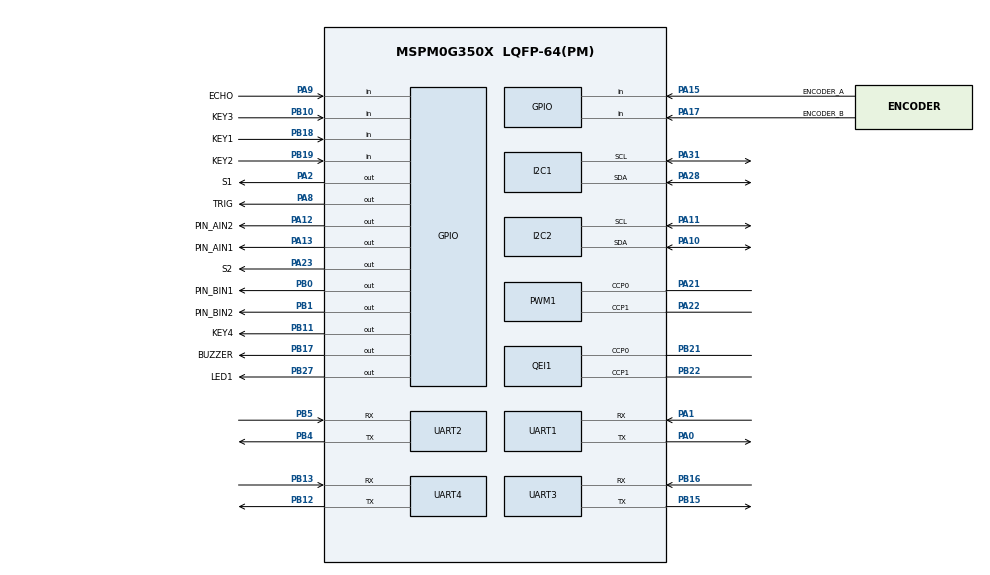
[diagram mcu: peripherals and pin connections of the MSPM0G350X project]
/**
 * @cliArgs --device "MSPM0G350X" --part "Default" --package "LQFP-64(PM)" --product "mspm0_sdk@2.10.00.04"
 * @versions {"tool":"1.26.2+4477"}
 */

/**
 * Import the modules used in this configuration.
 */
const ADC12  = scripting.addModule("/ti/driverlib/ADC12", {}, false);
const ADC121 = ADC12.addInstance();
const GPIO   = scripting.addModule("/ti/driverlib/GPIO", {}, false);
const GPIO1  = GPIO.addInstance();
const GPIO2  = GPIO.addInstance();
const GPIO3  = GPIO.addInstance();
const GPIO4  = GPIO.addInstance();
const GPIO5  = GPIO.addInstance();
const GPIO6  = GPIO.addInstance();
const GPIO7  = GPIO.addInstance();
const I2C    = scripting.addModule("/ti/driverlib/I2C", {}, false);
const I2C1   = I2C.addInstance();
const I2C2   = I2C.addInstance();
const PWM    = scripting.addModule("/ti/driverlib/PWM", {}, false);
const PWM1   = PWM.addInstance();
const QEI    = scripting.addModule("/ti/driverlib/QEI", {}, false);
const QEI1   = QEI.addInstance();
const SYSCTL = scripting.addModule("/ti/driverlib/SYSCTL");
const UART   = scripting.addModule("/ti/driverlib/UART", {}, false);
const UART1  = UART.addInstance();
const UART2  = UART.addInstance();
const UART3  = UART.addInstance();
const UART4  = UART.addInstance();

/**
 * Write custom configuration values to the imported modules.
 */
ADC121.$name                       = "TRACK";
ADC121.adcMem11chansel             = "DL_ADC12_INPUT_CHAN_12";
ADC121.adcMem0chansel              = "DL_ADC12_INPUT_CHAN_12";
ADC121.peripheral.$assign          = "ADC0";
ADC121.peripheral.adcPin12.$assign = "PA14";
ADC121.adcPin12Config.$name        = "ti_driverlib_gpio_GPIOPinGeneric16";

const Board = scripting.addModule("/ti/driverlib/Board", {}, false);

GPIO1.$name                         = "GPIO_QEI_RIGHT_MOTOR";
GPIO1.associatedPins.create(2);
GPIO1.associatedPins[0].$name       = "ENCODER_A";
GPIO1.associatedPins[0].direction   = "INPUT";
GPIO1.associatedPins[0].interruptEn = true;
GPIO1.associatedPins[0].polarity    = "RISE_FALL";
GPIO1.associatedPins[0].pin.$assign = "PA15";
GPIO1.associatedPins[1].$name       = "ENCODER_B";
GPIO1.associatedPins[1].direction   = "INPUT";
GPIO1.associatedPins[1].pin.$assign = "PA17";

GPIO2.$name                         = "GPIO_MOTOR_DIRECTION";
GPIO2.associatedPins.create(4);
GPIO2.associatedPins[0].$name       = "PIN_AIN2";
GPIO2.associatedPins[0].pin.$assign = "PA12";
GPIO2.associatedPins[1].$name       = "PIN_AIN1";
GPIO2.associatedPins[1].pin.$assign = "PA13";
GPIO2.associatedPins[2].$name       = "PIN_BIN1";
GPIO2.associatedPins[2].pin.$assign = "PB0";
GPIO2.associatedPins[3].$name       = "PIN_BIN2";
GPIO2.associatedPins[3].pin.$assign = "PB1";

GPIO3.$name                              = "GPIO_GRP_KEY";
GPIO3.port                               = "PORTB";
GPIO3.associatedPins.create(4);
GPIO3.associatedPins[0].direction        = "INPUT";
GPIO3.associatedPins[0].$name            = "KEY2";
GPIO3.associatedPins[0].assignedPin      = "19";
GPIO3.associatedPins[0].internalResistor = "PULL_UP";
GPIO3.associatedPins[0].pin.$assign      = "PB19";
GPIO3.associatedPins[1].$name            = "KEY1";
GPIO3.associatedPins[1].direction        = "INPUT";
GPIO3.associatedPins[1].pin.$assign      = "PB18";
GPIO3.associatedPins[2].$name            = "KEY3";
GPIO3.associatedPins[2].direction        = "INPUT";
GPIO3.associatedPins[2].internalResistor = "PULL_UP";
GPIO3.associatedPins[2].pin.$assign      = "PB10";
GPIO3.associatedPins[3].$name            = "KEY4";
GPIO3.associatedPins[3].pin.$assign      = "PB11";

GPIO4.$name                          = "GPIO_GRP_LED";
GPIO4.port                           = "PORTB";
GPIO4.associatedPins[0].$name        = "LED1";
GPIO4.associatedPins[0].assignedPin  = "27";
GPIO4.associatedPins[0].initialValue = "SET";
GPIO4.associatedPins[0].pin.$assign  = "PB27";

GPIO5.$name                         = "GPIO_GRP_TRACK";
GPIO5.port                          = "PORTA";
GPIO5.associatedPins.create(3);
GPIO5.associatedPins[0].$name       = "S1";
GPIO5.associatedPins[0].pin.$assign = "PA2";
GPIO5.associatedPins[1].$name       = "S2";
GPIO5.associatedPins[1].pin.$assign = "PA23";
GPIO5.associatedPins[2].$name       = "S0";

GPIO6.$name                         = "GPIO_GRP_BUZZER";
GPIO6.port                          = "PORTB";
GPIO6.associatedPins[0].$name       = "BUZZER";
GPIO6.associatedPins[0].pin.$assign = "PB17";

GPIO7.$name                         = "GPIO_GRP_HCSR04";
GPIO7.port                          = "PORTA";
GPIO7.associatedPins.create(2);
GPIO7.associatedPins[0].$name       = "TRIG";
GPIO7.associatedPins[0].pin.$assign = "PA8";
GPIO7.associatedPins[1].$name       = "ECHO";
GPIO7.associatedPins[1].direction   = "INPUT";
GPIO7.associatedPins[1].pin.$assign = "PA9";

I2C1.$name                             = "I2C_OLED";
I2C1.peripheral.$assign                = "I2C0";
I2C1.peripheral.sdaPin.$assign         = "PA28";
I2C1.peripheral.sclPin.$assign         = "PA31";
I2C1.sdaPinConfig.hideOutputInversion  = scripting.forceWrite(false);
I2C1.sdaPinConfig.onlyInternalResistor = scripting.forceWrite(false);
I2C1.sdaPinConfig.passedPeripheralType = scripting.forceWrite("Digital");
I2C1.sdaPinConfig.$name                = "ti_driverlib_gpio_GPIOPinGeneric4";
I2C1.sclPinConfig.hideOutputInversion  = scripting.forceWrite(false);
I2C1.sclPinConfig.onlyInternalResistor = scripting.forceWrite(false);
I2C1.sclPinConfig.passedPeripheralType = scripting.forceWrite("Digital");
I2C1.sclPinConfig.$name                = "ti_driverlib_gpio_GPIOPinGeneric5";

I2C2.$name                             = "I2C_MPU";
I2C2.peripheral.$assign                = "I2C1";
I2C2.peripheral.sdaPin.$assign         = "PA10";
I2C2.peripheral.sclPin.$assign         = "PA11";
I2C2.sdaPinConfig.hideOutputInversion  = scripting.forceWrite(false);
I2C2.sdaPinConfig.onlyInternalResistor = scripting.forceWrite(false);
I2C2.sdaPinConfig.passedPeripheralType = scripting.forceWrite("Digital");
I2C2.sdaPinConfig.$name                = "ti_driverlib_gpio_GPIOPinGeneric6";
I2C2.sclPinConfig.hideOutputInversion  = scripting.forceWrite(false);
I2C2.sclPinConfig.onlyInternalResistor = scripting.forceWrite(false);
I2C2.sclPinConfig.passedPeripheralType = scripting.forceWrite("Digital");
I2C2.sclPinConfig.$name                = "ti_driverlib_gpio_GPIOPinGeneric7";

PWM1.$name                              = "PWM_MOTOR";
PWM1.peripheral.$assign                 = "TIMA0";
PWM1.peripheral.ccp0Pin.$assign         = "PA21";
PWM1.peripheral.ccp1Pin.$assign         = "PA22";
PWM1.PWM_CHANNEL_0.$name                = "ti_driverlib_pwm_PWMTimerCC0";
PWM1.PWM_CHANNEL_1.$name                = "ti_driverlib_pwm_PWMTimerCC1";
PWM1.ccp0PinConfig.direction            = scripting.forceWrite("OUTPUT");
PWM1.ccp0PinConfig.hideOutputInversion  = scripting.forceWrite(false);
PWM1.ccp0PinConfig.onlyInternalResistor = scripting.forceWrite(false);
PWM1.ccp0PinConfig.passedPeripheralType = scripting.forceWrite("Digital");
PWM1.ccp0PinConfig.$name                = "ti_driverlib_gpio_GPIOPinGeneric2";
PWM1.ccp1PinConfig.direction            = scripting.forceWrite("OUTPUT");
PWM1.ccp1PinConfig.hideOutputInversion  = scripting.forceWrite(false);
PWM1.ccp1PinConfig.onlyInternalResistor = scripting.forceWrite(false);
PWM1.ccp1PinConfig.passedPeripheralType = scripting.forceWrite("Digital");
PWM1.ccp1PinConfig.$name                = "ti_driverlib_gpio_GPIOPinGeneric3";

QEI1.$name                              = "QEI_LEFT_MOTOR";
QEI1.peripheral.$assign                 = "TIMG8";
QEI1.peripheral.ccp0Pin.$assign         = "PB21";
QEI1.peripheral.ccp1Pin.$assign         = "PB22";
QEI1.ccp0PinConfig.hideOutputInversion  = scripting.forceWrite(false);
QEI1.ccp0PinConfig.onlyInternalResistor = scripting.forceWrite(false);
QEI1.ccp0PinConfig.passedPeripheralType = scripting.forceWrite("Digital");
QEI1.ccp0PinConfig.$name                = "ti_driverlib_gpio_GPIOPinGeneric0";
QEI1.ccp1PinConfig.hideOutputInversion  = scripting.forceWrite(false);
QEI1.ccp1PinConfig.onlyInternalResistor = scripting.forceWrite(false);
QEI1.ccp1PinConfig.passedPeripheralType = scripting.forceWrite("Digital");
QEI1.ccp1PinConfig.$name                = "ti_driverlib_gpio_GPIOPinGeneric1";

SYSCTL.forceDefaultClkConfig = true;

UART1.$name                            = "UART_Bluetooth";
UART1.targetBaudRate                   = 115200;
UART1.peripheral.$assign               = "UART0";
UART1.peripheral.rxPin.$assign         = "PA1";
UART1.peripheral.txPin.$assign         = "PA0";
UART1.txPinConfig.direction            = scripting.forceWrite("OUTPUT");
UART1.txPinConfig.hideOutputInversion  = scripting.forceWrite(false);
UART1.txPinConfig.onlyInternalResistor = scripting.forceWrite(false);
UART1.txPinConfig.passedPeripheralType = scripting.forceWrite("Digital");
UART1.txPinConfig.$name                = "ti_driverlib_gpio_GPIOPinGeneric8";
UART1.rxPinConfig.hideOutputInversion  = scripting.forceWrite(false);
UART1.rxPinConfig.onlyInternalResistor = scripting.forceWrite(false);
UART1.rxPinConfig.passedPeripheralType = scripting.forceWrite("Digital");
UART1.rxPinConfig.$name                = "ti_driverlib_gpio_GPIOPinGeneric9";

UART2.$name                            = "UART_K230";
UART2.targetBaudRate                   = 115200;
UART2.peripheral.$assign               = "UART1";
UART2.peripheral.rxPin.$assign         = "PB5";
UART2.peripheral.txPin.$assign         = "PB4";
UART2.txPinConfig.direction            = scripting.forceWrite("OUTPUT");
UART2.txPinConfig.hideOutputInversion  = scripting.forceWrite(false);
UART2.txPinConfig.onlyInternalResistor = scripting.forceWrite(false);
UART2.txPinConfig.passedPeripheralType = scripting.forceWrite("Digital");
UART2.txPinConfig.$name                = "ti_driverlib_gpio_GPIOPinGeneric10";
UART2.rxPinConfig.hideOutputInversion  = scripting.forceWrite(false);
UART2.rxPinConfig.onlyInternalResistor = scripting.forceWrite(false);
UART2.rxPinConfig.passedPeripheralType = scripting.forceWrite("Digital");
UART2.rxPinConfig.$name                = "ti_driverlib_gpio_GPIOPinGeneric11";

UART3.targetBaudRate                   = 115200;
UART3.$name                            = "UART_BLDC";
UART3.peripheral.$assign               = "UART2";
UART3.peripheral.rxPin.$assign         = "PB16";
UART3.peripheral.txPin.$assign         = "PB15";
UART3.txPinConfig.direction            = scripting.forceWrite("OUTPUT");
UART3.txPinConfig.hideOutputInversion  = scripting.forceWrite(false);
UART3.txPinConfig.onlyInternalResistor = scripting.forceWrite(false);
UART3.txPinConfig.passedPeripheralType = scripting.forceWrite("Digital");
UART3.txPinConfig.$name                = "ti_driverlib_gpio_GPIOPinGeneric12";
UART3.rxPinConfig.hideOutputInversion  = scripting.forceWrite(false);
UART3.rxPinConfig.onlyInternalResistor = scripting.forceWrite(false);
UART3.rxPinConfig.passedPeripheralType = scripting.forceWrite("Digital");
UART3.rxPinConfig.$name                = "ti_driverlib_gpio_GPIOPinGeneric13";

UART4.targetBaudRate                   = 115200;
UART4.$name                            = "UART_reserved";
UART4.peripheral.$assign               = "UART3";
UART4.peripheral.rxPin.$assign         = "PB13";
UART4.peripheral.txPin.$assign         = "PB12";
UART4.txPinConfig.direction            = scripting.forceWrite("OUTPUT");
UART4.txPinConfig.hideOutputInversion  = scripting.forceWrite(false);
UART4.txPinConfig.onlyInternalResistor = scripting.forceWrite(false);
UART4.txPinConfig.passedPeripheralType = scripting.forceWrite("Digital");
UART4.txPinConfig.$name                = "ti_driverlib_gpio_GPIOPinGeneric14";
UART4.rxPinConfig.hideOutputInversion  = scripting.forceWrite(false);
UART4.rxPinConfig.onlyInternalResistor = scripting.forceWrite(false);
UART4.rxPinConfig.passedPeripheralType = scripting.forceWrite("Digital");
UART4.rxPinConfig.$name                = "ti_driverlib_gpio_GPIOPinGeneric15";

/**
 * Pinmux solution for unlocked pins/peripherals. This ensures that minor changes to the automatic solver in a future
 * version of the tool will not impact the pinmux you originally saw.  These lines can be completely deleted in order to
 * re-solve from scratch.
 */
Board.peripheral.$suggestSolution            = "DEBUGSS";
Board.peripheral.swclkPin.$suggestSolution   = "PA20";
Board.peripheral.swdioPin.$suggestSolution   = "PA19";
GPIO5.associatedPins[2].pin.$suggestSolution = "PA16";
SYSCTL.peripheral.$suggestSolution           = "SYSCTL";
